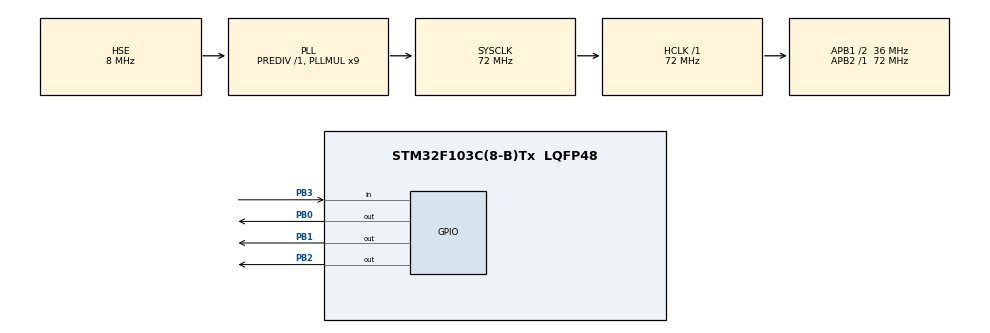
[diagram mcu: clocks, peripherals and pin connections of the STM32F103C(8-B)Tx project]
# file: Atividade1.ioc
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FREERTOS.Tasks01=defaultTask,24,128,StartDefaultTask,Default,NULL,Dynamic,NULL,NULL;Tarefa1,24,128,Tarefa1Function,Default,NULL,Dynamic,NULL,NULL;Tarefa2,32,128,Tarefa2Function,Default,NULL,Dynamic,NULL,NULL;Tarefa3,8,128,Tarefa3Function,Default,NULL,Dynamic,NULL,NULL
Mcu.Family=STM32F1
Mcu.Name=STM32F103C(8-B)Tx
Mcu.Package=LQFP48
NVIC.PriorityGroup=NVIC_PRIORITYGROUP_4
NVIC.TIM1_UP_IRQn=true\:15\:0\:false\:false\:true\:false\:false\:true
NVIC.TimeBase=TIM1_UP_IRQn
NVIC.TimeBaseIP=TIM1
PA13.Mode=Serial_Wire
PA13.Signal=SYS_JTMS-SWDIO
PA14.Mode=Serial_Wire
PA14.Signal=SYS_JTCK-SWCLK
PB0.Signal=GPIO_Output
PB1.Signal=GPIO_Output
PB2.Signal=GPIO_Output
PB3.Signal=GPIO_Input
PD0-OSC_IN.Mode=HSE-External-Oscillator
PD0-OSC_IN.Signal=RCC_OSC_IN
PD1-OSC_OUT.Mode=HSE-External-Oscillator
PD1-OSC_OUT.Signal=RCC_OSC_OUT
ProjectManager.HeapSize=0x200
ProjectManager.StackSize=0x400
ProjectManager.TargetToolchain=MDK-ARM V5.27
RCC.AHBFreq_Value=72000000
RCC.APB1CLKDivider=RCC_HCLK_DIV2
RCC.APB1Freq_Value=36000000
RCC.APB1TimFreq_Value=72000000
RCC.APB2Freq_Value=72000000
RCC.APB2TimFreq_Value=72000000
RCC.HCLKFreq_Value=72000000
RCC.PLLMUL=RCC_PLL_MUL9
RCC.PLLSourceVirtual=RCC_PLLSOURCE_HSE
RCC.SYSCLKFreq_VALUE=72000000
RCC.SYSCLKSource=RCC_SYSCLKSOURCE_PLLCLK
RCC.USBFreq_Value=72000000
VP_FREERTOS_VS_CMSIS_V2.Mode=CMSIS_V2
VP_SYS_VS_tim1.Mode=TIM1
board=custom

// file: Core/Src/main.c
/* USER CODE BEGIN Header */
/**
  ******************************************************************************
  * @file           : main.c
  * @brief          : Main program body
  ******************************************************************************
  * @attention
  *
  * <h2><center>&copy; Copyright (c) 2021 STMicroelectronics.
  * All rights reserved.</center></h2>
  *
  * This software component is licensed by ST under Ultimate Liberty license
  * SLA0044, the "License"; You may not use this file except in compliance with
  * the License. You may obtain a copy of the License at:
  *                             www.st.com/SLA0044
  *
  ******************************************************************************
  */
/* USER CODE END Header */
#include "main.h"
#include "cmsis_os.h"

/* Definitions for defaultTask */
osThreadId_t defaultTaskHandle;
const osThreadAttr_t defaultTask_attributes = {
  .name = "defaultTask",
  .stack_size = 128 * 4,
  .priority = (osPriority_t) osPriorityNormal,
};
/* Definitions for Tarefa1 */
osThreadId_t Tarefa1Handle;
const osThreadAttr_t Tarefa1_attributes = {
  .name = "Tarefa1",
  .stack_size = 128 * 4,
  .priority = (osPriority_t) osPriorityNormal,
};
/* Definitions for Tarefa2 */
osThreadId_t Tarefa2Handle;
const osThreadAttr_t Tarefa2_attributes = {
  .name = "Tarefa2",
  .stack_size = 128 * 4,
  .priority = (osPriority_t) osPriorityAboveNormal,
};
/* Definitions for Tarefa3 */
osThreadId_t Tarefa3Handle;
const osThreadAttr_t Tarefa3_attributes = {
  .name = "Tarefa3",
  .stack_size = 128 * 4,
  .priority = (osPriority_t) osPriorityLow,
};

void SystemClock_Config(void);
static void MX_GPIO_Init(void);
void StartDefaultTask(void *argument);
void Tarefa1Function(void *argument);
void Tarefa2Function(void *argument);
void Tarefa3Function(void *argument);

int main(void)
{

  /* MCU Configuration--------------------------------------------------------*/

  /* Reset of all peripherals, Initializes the Flash interface and the Systick. */
  HAL_Init();

  /* Configure the system clock */
  SystemClock_Config();

  /* Initialize all configured peripherals */
  MX_GPIO_Init();

  /* Init scheduler */
  osKernelInitialize();

  /* Create the thread(s) */
  /* creation of defaultTask */
  defaultTaskHandle = osThreadNew(StartDefaultTask, NULL, &defaultTask_attributes);

  /* creation of Tarefa1 */
  Tarefa1Handle = osThreadNew(Tarefa1Function, NULL, &Tarefa1_attributes);

  /* creation of Tarefa2 */
  Tarefa2Handle = osThreadNew(Tarefa2Function, NULL, &Tarefa2_attributes);

  /* creation of Tarefa3 */
  Tarefa3Handle = osThreadNew(Tarefa3Function, NULL, &Tarefa3_attributes);

  /* Start scheduler */
  osKernelStart();

  /* We should never get here as control is now taken by the scheduler */
  /* Infinite loop */
  while (1)
  {

  }
}

void SystemClock_Config(void)
{
  RCC_OscInitTypeDef RCC_OscInitStruct = {0};
  RCC_ClkInitTypeDef RCC_ClkInitStruct = {0};

  /** Initializes the RCC Oscillators according to the specified parameters
  * in the RCC_OscInitTypeDef structure.
  */
  RCC_OscInitStruct.OscillatorType = RCC_OSCILLATORTYPE_HSE;
  RCC_OscInitStruct.HSEState = RCC_HSE_ON;
  RCC_OscInitStruct.HSEPredivValue = RCC_HSE_PREDIV_DIV1;
  RCC_OscInitStruct.HSIState = RCC_HSI_ON;
  RCC_OscInitStruct.PLL.PLLState = RCC_PLL_ON;
  RCC_OscInitStruct.PLL.PLLSource = RCC_PLLSOURCE_HSE;
  RCC_OscInitStruct.PLL.PLLMUL = RCC_PLL_MUL9;
  if (HAL_RCC_OscConfig(&RCC_OscInitStruct) != HAL_OK)
  {
    Error_Handler();
  }
  /** Initializes the CPU, AHB and APB buses clocks
  */
  RCC_ClkInitStruct.ClockType = RCC_CLOCKTYPE_HCLK|RCC_CLOCKTYPE_SYSCLK
                              |RCC_CLOCKTYPE_PCLK1|RCC_CLOCKTYPE_PCLK2;
  RCC_ClkInitStruct.SYSCLKSource = RCC_SYSCLKSOURCE_PLLCLK;
  RCC_ClkInitStruct.AHBCLKDivider = RCC_SYSCLK_DIV1;
  RCC_ClkInitStruct.APB1CLKDivider = RCC_HCLK_DIV2;
  RCC_ClkInitStruct.APB2CLKDivider = RCC_HCLK_DIV1;

  if (HAL_RCC_ClockConfig(&RCC_ClkInitStruct, FLASH_LATENCY_2) != HAL_OK)
  {
    Error_Handler();
  }
}

static void MX_GPIO_Init(void)
{
  GPIO_InitTypeDef GPIO_InitStruct = {0};

  /* GPIO Ports Clock Enable */
  __HAL_RCC_GPIOD_CLK_ENABLE();
  __HAL_RCC_GPIOB_CLK_ENABLE();
  __HAL_RCC_GPIOA_CLK_ENABLE();

  /*Configure GPIO pin Output Level */
  HAL_GPIO_WritePin(GPIOB, GPIO_PIN_0|GPIO_PIN_1|GPIO_PIN_2, GPIO_PIN_RESET);

  /*Configure GPIO pins : PB0 PB1 PB2 */
  GPIO_InitStruct.Pin = GPIO_PIN_0|GPIO_PIN_1|GPIO_PIN_2;
  GPIO_InitStruct.Mode = GPIO_MODE_OUTPUT_PP;
  GPIO_InitStruct.Pull = GPIO_NOPULL;
  GPIO_InitStruct.Speed = GPIO_SPEED_FREQ_LOW;
  HAL_GPIO_Init(GPIOB, &GPIO_InitStruct);

  /*Configure GPIO pin : PB3 */
  GPIO_InitStruct.Pin = GPIO_PIN_3;
  GPIO_InitStruct.Mode = GPIO_MODE_INPUT;
  GPIO_InitStruct.Pull = GPIO_NOPULL;
  HAL_GPIO_Init(GPIOB, &GPIO_InitStruct);

}

void StartDefaultTask(void *argument)
{
  for(;;)
  {
		osDelay(1);
  }
}

void Tarefa1Function(void *argument)
{
  /* USER CODE BEGIN Tarefa1Function */
  /* Infinite loop */
  for(;;)
  {
    osDelay(100);
		HAL_GPIO_TogglePin (GPIOB,GPIO_PIN_0 );

  }
  /* USER CODE END Tarefa1Function */
}

void Tarefa2Function(void *argument)
{
  /* USER CODE BEGIN Tarefa2Function */
  /* Infinite loop */
  for(;;)
  {
    osDelay(50);
		HAL_GPIO_TogglePin (GPIOB,GPIO_PIN_1 );

  }
  /* USER CODE END Tarefa2Function */
}

void Tarefa3Function(void *argument)
{
  /* USER CODE BEGIN Tarefa3Function */
  /* Infinite loop */
  for(;;)
  {
		if( HAL_GPIO_ReadPin (GPIOB,GPIO_PIN_3 )==GPIO_PIN_SET) {
			HAL_GPIO_TogglePin (GPIOB,GPIO_PIN_2 );
		}
			osDelay(10);
  }
  /* USER CODE END Tarefa3Function */
}

void HAL_TIM_PeriodElapsedCallback(TIM_HandleTypeDef *htim)
{
  if (htim->Instance == TIM1) {
    HAL_IncTick();
  }
}

void Error_Handler(void)
{
  __disable_irq();
  while (1)
  {
  }
}

/************************ (C) COPYRIGHT STMicroelectronics *****END OF FILE****/
